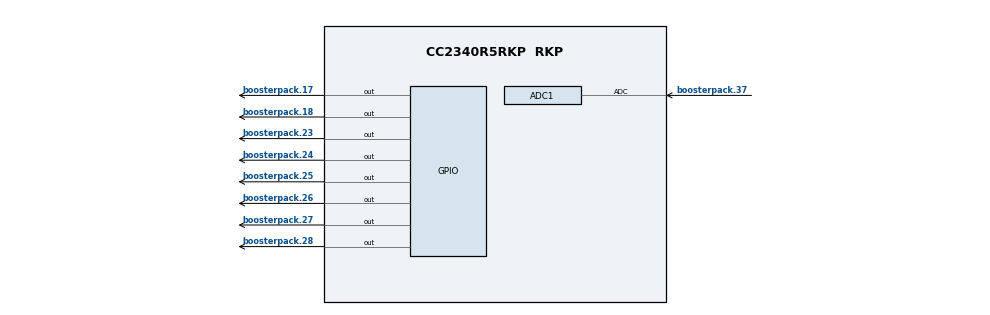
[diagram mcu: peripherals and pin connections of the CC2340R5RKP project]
/**
 * @cliArgs --board "/ti/boards/LP_EM_CC2340R5" --device "CC2340R5RKP" --part "Default" --package "RKP" --rtos "freertos" --product "simplelink_lowpower_f3_sdk@9.12.00.19"
 * @versions {"tool":"1.23.2+4156"}
 */

/**
 * Import the modules used in this configuration.
 */
const FreeRTOS    = scripting.addModule("/freertos/FreeRTOS");
const ble         = scripting.addModule("/ti/ble/ble");
const CCFG        = scripting.addModule("/ti/devices/CCFG");
const rfdesign    = scripting.addModule("/ti/devices/radioconfig/rfdesign");
const Display     = scripting.addModule("/ti/display/Display");
const Display1    = Display.addInstance();
const ADC         = scripting.addModule("/ti/drivers/ADC", {}, false);
const ADC1        = ADC.addInstance();
const AESCCM      = scripting.addModule("/ti/drivers/AESCCM");
const AESCCM1     = AESCCM.addInstance();
const AESCTRDRBG  = scripting.addModule("/ti/drivers/AESCTRDRBG");
const AESCTRDRBG1 = AESCTRDRBG.addInstance();
const AESECB      = scripting.addModule("/ti/drivers/AESECB");
const AESECB1     = AESECB.addInstance();
const ECDH        = scripting.addModule("/ti/drivers/ECDH");
const ECDH1       = ECDH.addInstance();
const GPIO        = scripting.addModule("/ti/drivers/GPIO");
const GPIO2       = GPIO.addInstance();
const GPIO3       = GPIO.addInstance();
const GPIO4       = GPIO.addInstance();
const GPIO5       = GPIO.addInstance();
const GPIO6       = GPIO.addInstance();
const GPIO7       = GPIO.addInstance();
const GPIO8       = GPIO.addInstance();
const GPIO9       = GPIO.addInstance();
const GPIO10      = GPIO.addInstance();
const GPIO11      = GPIO.addInstance();
const I2C         = scripting.addModule("/ti/drivers/I2C", {}, false);
const I2C1        = I2C.addInstance();
const NVS         = scripting.addModule("/ti/drivers/NVS");
const NVS1        = NVS.addInstance();
const Power       = scripting.addModule("/ti/drivers/Power");
const RCL         = scripting.addModule("/ti/drivers/RCL");
const RNG         = scripting.addModule("/ti/drivers/RNG");
const RNG1        = RNG.addInstance();
const Button      = scripting.addModule("/ti/drivers/apps/Button", {}, false);
const Button1     = Button.addInstance();
const Button2     = Button.addInstance();
const Settings    = scripting.addModule("/ti/posix/freertos/Settings");

/**
 * Write custom configuration values to the imported modules.
 */
FreeRTOS.heapSize       = 0x00004D50;
FreeRTOS.timerStackSize = 0x00000190;
FreeRTOS.idleStackSize  = 0x00000130;

ble.basicBLE                                                   = true;
ble.disDevBySerUuid                                            = true;
ble.numOfAdvSets                                               = 1;
ble.numOfDefAdvSets                                            = 1;
ble.deviceName                                                 = "BLE Sensor Project";
ble.defaultTxPowerValue                                        = "5";
ble.radioConfig.codeExportConfig.$name                         = "ti_devices_radioconfig_code_export_param0";
ble.adcNoiseConfig.codeExportConfig.$name                      = "ti_devices_radioconfig_code_export_param1";
ble.bleCsConfig.codeExportConfig.$name                         = "ti_devices_radioconfig_code_export_param2";
ble.connUpdateParamsPeripheral.$name                           = "ti_ble_general_ble_conn_update_params0";
ble.advSet1.$name                                              = "ti_ble_broadcaster_advertisement_set0";
ble.advSet1.advParam1.$name                                    = "ti_ble_broadcaster_advertisement_params0";
ble.advSet1.advData1.$name                                     = "ti_ble_broadcaster_advertisement_data0";
ble.advSet1.advData1.GAP_ADTYPE_16BIT_MORE                     = true;
ble.advSet1.advData1.numOfUUIDs16More                          = 1;
ble.advSet1.advData1.UUID016More                               = 0xFFF0;
ble.advSet1.scanRes1.$name                                     = "ti_ble_broadcaster_advertisement_data1";
ble.advSet1.scanRes1.GAP_ADTYPE_PERIPHERAL_CONN_INTERVAL_RANGE = true;

CCFG.ccfgTemplate.$name = "ti_devices_CCFG_CCFGCC23X0Template0";

Display1.$name                    = "CONFIG_Display_0";
Display1.$hardware                = system.deviceData.board.components.XDS110UART;
Display1.enableANSI               = true;
Display1.uartBufferSize           = 128;
Display1.uart.$name               = "CONFIG_DISPLAY_UART";
Display1.uart.txPinInstance.$name = "CONFIG_PIN_UART_TX";
Display1.uart.rxPinInstance.$name = "CONFIG_PIN_UART_RX";

ADC1.$name                         = "CONFIG_ADC_DRV5055";
ADC1.adcChannel.adc.adcPin.$assign = "boosterpack.37";

AESCCM1.$name = "CONFIG_AESCCM0";

AESCTRDRBG1.$name = "CONFIG_AESCTRDRBG_0";

AESECB1.$name = "CONFIG_AESECB0";

ECDH1.$name = "CONFIG_ECDH0";

GPIO2.$hardware = system.deviceData.board.components.LED_GREEN;
GPIO2.$name     = "CONFIG_GPIO_LED_GREEN";

GPIO3.$hardware = system.deviceData.board.components.LED_RED;
GPIO3.$name     = "CONFIG_GPIO_LED_RED";

GPIO4.mode               = "Output";
GPIO4.$name              = "CONFIG_GPIO_TMP116_PWR";
GPIO4.initialOutputState = "High";
GPIO4.gpioPin.$assign    = "boosterpack.28";

GPIO5.$name              = "CONFIG_GPIO_OPT3001_POWER";
GPIO5.mode               = "Output";
GPIO5.initialOutputState = "High";
GPIO5.gpioPin.$assign    = "boosterpack.27";

GPIO6.mode            = "Output";
GPIO6.$name           = "CONFIG_GPIO_DRV5055_POWER";
GPIO6.gpioPin.$assign = "boosterpack.24";

GPIO7.$name            = "CONFIG_GPIO_BMI160_INT1";
GPIO7.interruptTrigger = "Rising Edge";
GPIO7.gpioPin.$assign  = "boosterpack.17";

GPIO8.$name           = "CONFIG_GPIO_HDC2010_INT";
GPIO8.gpioPin.$assign = "boosterpack.23";

GPIO9.$name           = "CONFIG_GPIO_OPT3001_INT";
GPIO9.gpioPin.$assign = "boosterpack.25";

GPIO10.$name           = "CONFIG_GPIO_HDC2080_POWER";
GPIO10.mode            = "Output";
GPIO10.gpioPin.$assign = "boosterpack.18";

GPIO11.$name           = "CONFIG_GPIO_TMP116_INT";
GPIO11.gpioPin.$assign = "boosterpack.26";

I2C1.$name = "CONFIG_I2C_0";

NVS1.$name                    = "CONFIG_NVSINTERNAL";
NVS1.internalFlash.$name      = "ti_drivers_nvs_NVSLPF30";
NVS1.internalFlash.regionBase = 0x7D000;
NVS1.internalFlash.regionSize = 0x3000;

RNG.rngReturnBehavior = "RNG_RETURN_BEHAVIOR_BLOCKING";

RNG1.$name = "CONFIG_RNG_0";

Button1.$name     = "CONFIG_BUTTON_0";
Button1.$hardware = system.deviceData.board.components["BTN-1"];

Button2.$name     = "CONFIG_BUTTON_1";
Button2.$hardware = system.deviceData.board.components["BTN-2"];

/**
 * Pinmux solution for unlocked pins/peripherals. This ensures that minor changes to the automatic solver in a future
 * version of the tool will not impact the pinmux you originally saw.  These lines can be completely deleted in order to
 * re-solve from scratch.
 */
Display1.uart.uart.$suggestSolution              = "UART0";
Display1.uart.uart.dmaTxChannel.$suggestSolution = "DMA_CH1";
Display1.uart.uart.dmaRxChannel.$suggestSolution = "DMA_CH0";
Display1.uart.uart.txPin.$suggestSolution        = "boosterpack.4";
Display1.uart.uart.rxPin.$suggestSolution        = "boosterpack.3";
ADC1.adcChannel.adc.$suggestSolution             = "ADC";
GPIO2.gpioPin.$suggestSolution                   = "boosterpack.40";
GPIO3.gpioPin.$suggestSolution                   = "boosterpack.39";
I2C1.i2c.$suggestSolution                        = "I2C0";
I2C1.i2c.sdaPin.$suggestSolution                 = "boosterpack.10";
I2C1.i2c.sclPin.$suggestSolution                 = "boosterpack.9";
Button1.button.$suggestSolution                  = "boosterpack.13";
Button2.button.$suggestSolution                  = "boosterpack.12";
